# ATmega2560 register map
Vendor: Atmel; File version: 1.0
CPU: other r0p0, little endian, no MPU, no FPU, 4 interrupt priority bits
Registers are 8-bit, read-write, reset 0x0 unless marked. A register's access mark holds for its fields unless they carry their own. Offsets are from the block's base; [hi:lo] are bit positions; 'fields as' and 'values as' point back to an identical list.

## TC4 — Timer/Counter, 16-bit
Base 0x00000039
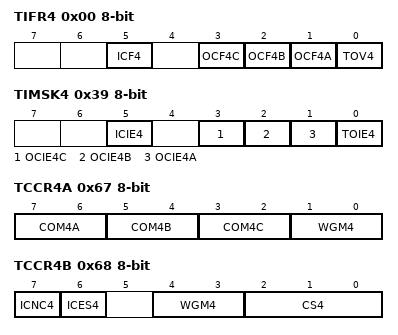
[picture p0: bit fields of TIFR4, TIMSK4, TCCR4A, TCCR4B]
0x00 TIFR4 — Timer/Counter4 Interrupt Flag register
  [5] ICF4 — Input Capture Flag 4
  [3] OCF4C — Output Compare Flag 4C
  [2] OCF4B — Output Compare Flag 4B
  [1] OCF4A — Output Compare Flag 4A
  [0] TOV4 — Timer/Counter4 Overflow Flag
0x39 TIMSK4 — Timer/Counter4 Interrupt Mask Register
  [5] ICIE4 — Timer/Counter4 Input Capture Interrupt Enable
  [3] OCIE4C — Timer/Counter4 Output Compare C Match Interrupt Enable
  [2] OCIE4B — Timer/Counter4 Output Compare B Match Interrupt Enable
  [1] OCIE4A — Timer/Counter4 Output Compare A Match Interrupt Enable
  [0] TOIE4 — Timer/Counter4 Overflow Interrupt Enable
0x67 TCCR4A — Timer/Counter4 Control Register A
  [7:6] COM4A — Compare Output Mode 1A, bits
    0=DISCONNECTED (Normal port operation, OCix disconnected); 1=MATCH_TOGGLE (Toggle OCix on Compare Match (Might depend on WGM)); 2=MATCH_CLEAR (Clear OCix on Compare Match (If PWM is enabled, OCix is set at BOTTOM)); 3=MATCH_SET (Set OCix on Compare Match (If PWM is enabled, OCix is cleared at BOTTOM))
  [5:4] COM4B — Compare Output Mode 4B, bits
    values as COM4A
  [3:2] COM4C — Compare Output Mode 4C, bits
    values as COM4A
  [1:0] WGM4 — Waveform Generation Mode
0x68 TCCR4B — Timer/Counter4 Control Register B
  [7] ICNC4 — Input Capture 4 Noise Canceler
  [6] ICES4 — Input Capture 4 Edge Select
  [4:3] WGM4 — Waveform Generation Mode
  [2:0] CS4 — Prescaler source of Timer/Counter 4
    0=NO_CLOCK (No clock source (Timer/Counter stopped)); 1=DIRECT (Running, No Prescaling); 2=PRESCALE_8 (Running, CLK/8); 3=PRESCALE_64 (Running, CLK/64); 4=PRESCALE_256 (Running, CLK/256); 5=PRESCALE_1024 (Running, CLK/1024); 6=EXT_FALLING (Running, ExtClk Tx Falling Edge); 7=EXT_RISING (Running, ExtClk Tx Rising Edge)
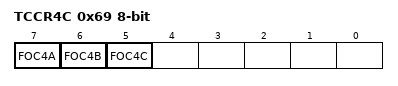
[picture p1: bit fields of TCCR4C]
0x69 TCCR4C — Timer/Counter 4 Control Register C
  [7] FOC4A wo — Force Output Compare 4A
  [6] FOC4B wo — Force Output Compare 4B
  [5] FOC4C wo — Force Output Compare 4C
0x6B TCNT4 16-bit (reset mask 0xFF) — Timer/Counter4 Bytes
0x6D ICR4 16-bit (reset mask 0xFF) — Timer/Counter4 Input Capture Register Bytes
0x6F OCR4A 16-bit (reset mask 0xFF) — Timer/Counter4 Output Compare Register A Bytes
0x71 OCR4B 16-bit (reset mask 0xFF) — Timer/Counter4 Output Compare Register B Bytes
0x73 OCR4C 16-bit (reset mask 0xFF) — Timer/Counter4 Output Compare Register B Bytes

## TC5 — Timer/Counter, 16-bit
Base 0x0000003A
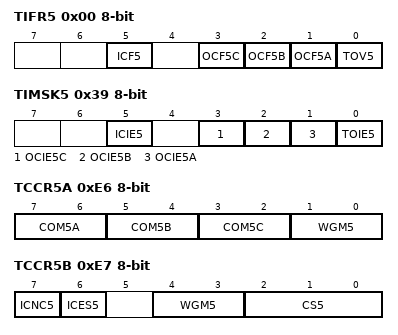
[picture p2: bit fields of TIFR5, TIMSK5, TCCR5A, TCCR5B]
0x00 TIFR5 — Timer/Counter5 Interrupt Flag register
  [5] ICF5 — Input Capture Flag 5
  [3] OCF5C — Output Compare Flag 5C
  [2] OCF5B — Output Compare Flag 5B
  [1] OCF5A — Output Compare Flag 5A
  [0] TOV5 — Timer/Counter5 Overflow Flag
0x39 TIMSK5 — Timer/Counter5 Interrupt Mask Register
  [5] ICIE5 — Timer/Counter5 Input Capture Interrupt Enable
  [3] OCIE5C — Timer/Counter5 Output Compare C Match Interrupt Enable
  [2] OCIE5B — Timer/Counter5 Output Compare B Match Interrupt Enable
  [1] OCIE5A — Timer/Counter5 Output Compare A Match Interrupt Enable
  [0] TOIE5 — Timer/Counter5 Overflow Interrupt Enable
0xE6 TCCR5A — Timer/Counter5 Control Register A
  [7:6] COM5A — Compare Output Mode 1A, bits
    0=DISCONNECTED (Normal port operation, OCix disconnected); 1=MATCH_TOGGLE (Toggle OCix on Compare Match (Might depend on WGM)); 2=MATCH_CLEAR (Clear OCix on Compare Match (If PWM is enabled, OCix is set at BOTTOM)); 3=MATCH_SET (Set OCix on Compare Match (If PWM is enabled, OCix is cleared at BOTTOM))
  [5:4] COM5B — Compare Output Mode 5B, bits
    values as COM5A
  [3:2] COM5C — Compare Output Mode 5C, bits
    values as COM5A
  [1:0] WGM5 — Waveform Generation Mode
0xE7 TCCR5B — Timer/Counter5 Control Register B
  [7] ICNC5 — Input Capture 5 Noise Canceler
  [6] ICES5 — Input Capture 5 Edge Select
  [4:3] WGM5 — Waveform Generation Mode
  [2:0] CS5 — Prescaler source of Timer/Counter 5
    0=NO_CLOCK (No clock source (Timer/Counter stopped)); 1=DIRECT (Running, No Prescaling); 2=PRESCALE_8 (Running, CLK/8); 3=PRESCALE_64 (Running, CLK/64); 4=PRESCALE_256 (Running, CLK/256); 5=PRESCALE_1024 (Running, CLK/1024); 6=EXT_FALLING (Running, ExtClk Tx Falling Edge); 7=EXT_RISING (Running, ExtClk Tx Rising Edge)
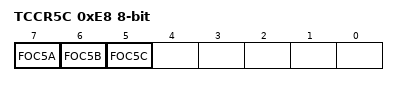
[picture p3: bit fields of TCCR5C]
0xE8 TCCR5C — Timer/Counter 5 Control Register C
  [7] FOC5A wo — Force Output Compare 5A
  [6] FOC5B wo — Force Output Compare 5B
  [5] FOC5C wo — Force Output Compare 5C
0xEA TCNT5 16-bit (reset mask 0xFF) — Timer/Counter5 Bytes
0xEC ICR5 16-bit (reset mask 0xFF) — Timer/Counter5 Input Capture Register Bytes
0xEE OCR5A 16-bit (reset mask 0xFF) — Timer/Counter5 Output Compare Register A Bytes
0xF0 OCR5B 16-bit (reset mask 0xFF) — Timer/Counter5 Output Compare Register B Bytes
0xF2 OCR5C 16-bit (reset mask 0xFF) — Timer/Counter5 Output Compare Register B Bytes
